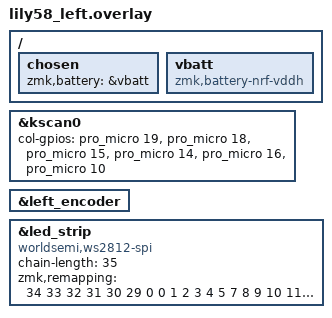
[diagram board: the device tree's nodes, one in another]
/*
 * Copyright (c) 2020 Pete Johanson
 *
 * SPDX-License-Identifier: MIT
 */

#include "lily58.dtsi"

&kscan0 {
    col-gpios
        = <&pro_micro 19 GPIO_ACTIVE_HIGH>
        , <&pro_micro 18 GPIO_ACTIVE_HIGH>
        , <&pro_micro 15 GPIO_ACTIVE_HIGH>
        , <&pro_micro 14 GPIO_ACTIVE_HIGH>
        , <&pro_micro 16 GPIO_ACTIVE_HIGH>
        , <&pro_micro 10 GPIO_ACTIVE_HIGH>
        ;
};

&left_encoder {
    status = "okay";
};
/ {
    chosen {
      zmk,battery = &vbatt;
    };

    vbatt: vbatt {
        compatible = "zmk,battery-nrf-vddh";
    };
};
&led_strip {
    compatible = "worldsemi,ws2812-spi";
    chain-length = <35>; 
    zmk,remapping = <
                     34 33 32 31 30 29  0
                      0  1  2  3  4  5  7 
                      8  9 10 11 12 13 14 
                     15 16 17 18 19 20 21
                     22 23 24 25 26 27 28
                    >;
};
